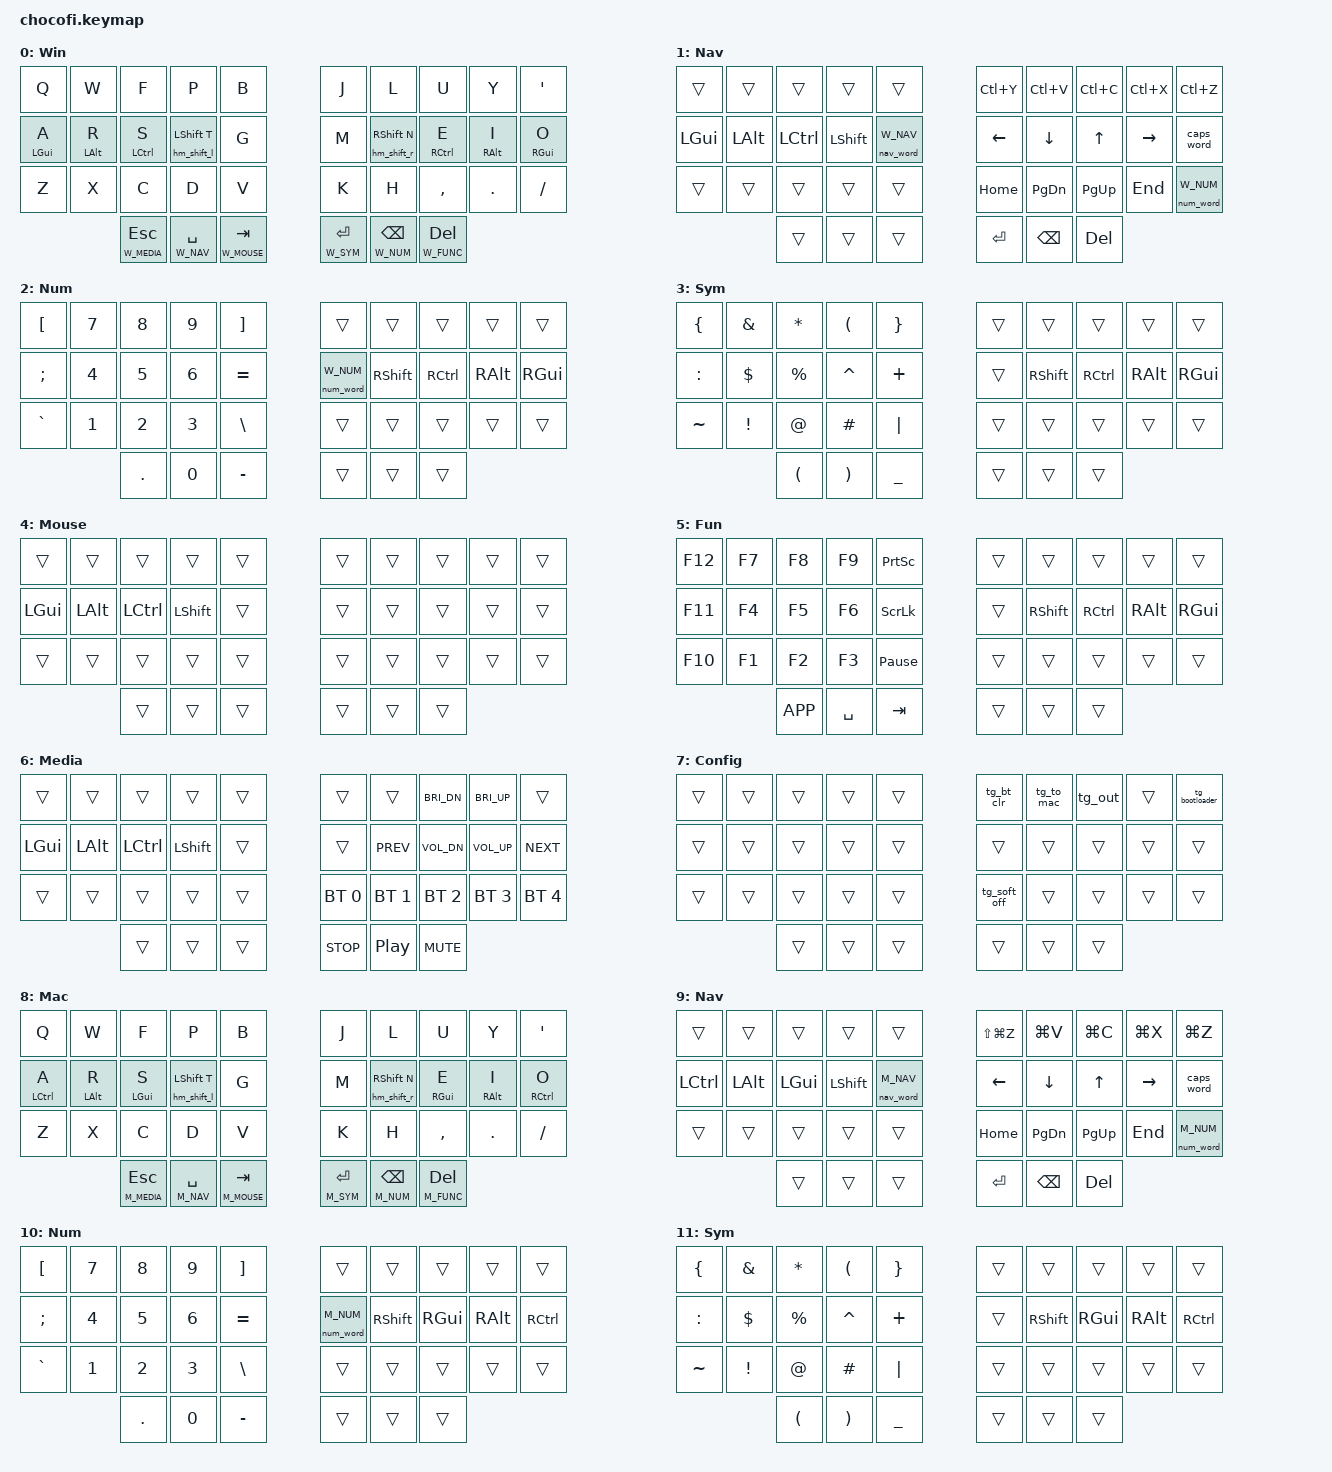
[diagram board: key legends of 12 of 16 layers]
#include <behaviors.dtsi>
#include <dt-bindings/zmk/keys.h>
#include <dt-bindings/zmk/bt.h>
#include <dt-bindings/zmk/outputs.h>

#include <zmk-helpers/helper.h>

#define ___ &trans

#define WIN       0
#define W_NAV     1
#define W_NUM     2
#define W_SYM     3
#define W_MOUSE   4
#define W_FUNC    5
#define W_MEDIA   6
#define W_CONFIG  7

#define MAC       8
#define M_NAV     9
#define M_NUM    10
#define M_SYM    11
#define M_MOUSE  12
#define M_FUNC   13
#define M_MEDIA  14
#define M_CONFIG 15

#include "settings.dtsi"
#include "behavior_homerow_mod.dtsi"
#include "behavior_tap_guard.dtsi"
#include "behavior_auto_layer.dtsi"

/ {
    conditional_layers {
        compatible = "zmk,conditional-layers";
        win_config_layer {
            if-layers = <W_MEDIA W_MOUSE>;
            then-layer = <W_CONFIG>;
        };
        mac_config_layer {
            if-layers = <M_MEDIA M_MOUSE>;
            then-layer = <M_CONFIG>;
        };
    };
};

&caps_word {
    continue-list = <UNDERSCORE MINUS BACKSPACE DELETE>;
};

/ {
    keymap {
        compatible = "zmk,keymap";

        win_layer {
            display-name = "Win";
            bindings = <
                // ╭────────────────────────┬────────────────────────┬────────────────────────┬────────────────────────┬────────────────────────╮    ╭────────────────────────┬────────────────────────┬────────────────────────┬───────────────────────┬────────────────────────╮
                      &kp Q                    &kp W                    &kp F                    &kp P                    &kp B                         &kp J                    &kp L                    &kp U                    &kp Y                   &kp SQT
                // ├────────────────────────┼────────────────────────┼────────────────────────┼────────────────────────┼────────────────────────┤    ├────────────────────────┼────────────────────────┼────────────────────────┼───────────────────────┼────────────────────────┤
                      &hm_l LGUI A             &hm_l LALT R             &hm_l LCTL S             &hm_shift_l LSHIFT T     &kp G                         &kp M                    &hm_shift_r RSHIFT N     &hm_r RCTL E             &hm_r RALT I            &hm_r RGUI O
                // ├────────────────────────┼────────────────────────┼────────────────────────┼────────────────────────┼────────────────────────┤    ├────────────────────────┼────────────────────────┼────────────────────────┼───────────────────────┼────────────────────────┤
                      &kp Z                    &kp X                    &kp C                    &kp D                    &kp V                         &kp K                    &kp H                    &kp COMMA                &kp DOT                 &kp FSLH
                // ╰────────────────────────┴────────────────────────┴────────────────────────┼────────────────────────┼────────────────────────┤    ├────────────────────────┼────────────────────────┼────────────────────────┼───────────────────────┼────────────────────────╯
                                                                        &lt W_MEDIA ESC          &lt W_NAV SPACE          &lt W_MOUSE TAB               &lt W_SYM RET            &lt W_NUM BSPC           &lt W_FUNC DEL
                //                                                   ╰────────────────────────┴────────────────────────┴────────────────────────╯    ╰────────────────────────┴────────────────────────┴────────────────────────╯
            >;
        };
        win_nav_layer {
            display-name = "Nav";
            bindings = <
                // ╭────────────────────────┬────────────────────────┬────────────────────────┬────────────────────────┬────────────────────────╮    ╭────────────────────────┬────────────────────────┬────────────────────────┬───────────────────────┬────────────────────────╮
                      ___                      ___                      ___                      ___                      ___                           &kp LC(Y)                &kp LC(V)                 &kp LC(C)                &kp LC(X)              &kp LC(Z)
                // ├────────────────────────┼────────────────────────┼────────────────────────┼────────────────────────┼────────────────────────┤    ├────────────────────────┼────────────────────────┼────────────────────────┼───────────────────────┼────────────────────────┤
                      &kp LGUI                 &kp LALT                 &kp LCTL                 &kp LSHIFT               &nav_word W_NAV               &kp LEFT                 &kp DOWN                  &kp UP                   &kp RIGHT              &caps_word
                // ├────────────────────────┼────────────────────────┼────────────────────────┼────────────────────────┼────────────────────────┤    ├────────────────────────┼────────────────────────┼────────────────────────┼───────────────────────┼────────────────────────┤
                      ___                      ___                      ___                      ___                      ___                           &kp HOME                 &kp PG_DN                 &kp PG_UP                &kp END                &num_word W_NUM
                // ╰────────────────────────┴────────────────────────┴────────────────────────┼────────────────────────┼────────────────────────┤    ├────────────────────────┼────────────────────────┼────────────────────────┼───────────────────────┼────────────────────────╯
                                                                        ___                      ___                      ___                           &kp RET                  &kp BSPC                  &kp DEL
                //                                                   ╰────────────────────────┴────────────────────────┴────────────────────────╯    ╰────────────────────────┴────────────────────────┴────────────────────────╯
            >;
        };
        win_num_layer {
            display-name = "Num";
            bindings = <
                // ╭────────────────────────┬────────────────────────┬────────────────────────┬────────────────────────┬────────────────────────╮    ╭────────────────────────┬────────────────────────┬────────────────────────┬───────────────────────┬────────────────────────╮
                      &kp LBKT                 &kp N7                   &kp N8                   &kp N9                   &kp RBKT                      ___                      ___                      ___                      ___                     ___
                // ├────────────────────────┼────────────────────────┼────────────────────────┼────────────────────────┼────────────────────────┤    ├────────────────────────┼────────────────────────┼────────────────────────┼───────────────────────┼────────────────────────┤
                      &kp SEMI                 &kp N4                   &kp N5                   &kp N6                   &kp EQUAL                     &num_word W_NUM          &kp RSHIFT               &kp RCTL                 &kp RALT                &kp RGUI
                // ├────────────────────────┼────────────────────────┼────────────────────────┼────────────────────────┼────────────────────────┤    ├────────────────────────┼────────────────────────┼────────────────────────┼───────────────────────┼────────────────────────┤
                      &kp GRAVE                &kp N1                   &kp N2                   &kp N3                   &kp BSLH                      ___                      ___                      ___                      ___                     ___
                // ╰────────────────────────┴────────────────────────┴────────────────────────┼────────────────────────┼────────────────────────┤    ├────────────────────────┼────────────────────────┼────────────────────────┼───────────────────────┼────────────────────────╯
                                                                        &kp DOT                  &kp N0                   &kp MINUS                     ___                      ___                      ___
                //                                                   ╰────────────────────────┴────────────────────────┴────────────────────────╯    ╰────────────────────────┴────────────────────────┴────────────────────────╯
            >;
        };
        win_sym_layer {
            display-name = "Sym";
            bindings = <
                // ╭────────────────────────┬────────────────────────┬────────────────────────┬────────────────────────┬────────────────────────╮    ╭────────────────────────┬────────────────────────┬────────────────────────┬───────────────────────┬────────────────────────╮
                      &kp LBRC                 &kp AMPS                 &kp STAR                 &kp LPAR                 &kp RBRC                      ___                      ___                      ___                      ___                     ___
                // ├────────────────────────┼────────────────────────┼────────────────────────┼────────────────────────┼────────────────────────┤    ├────────────────────────┼────────────────────────┼────────────────────────┼───────────────────────┼────────────────────────┤
                      &kp COLON                &kp DLLR                 &kp PRCNT                &kp CARET                &kp PLUS                      ___                      &kp RSHIFT               &kp RCTL                 &kp RALT                &kp RGUI
                // ├────────────────────────┼────────────────────────┼────────────────────────┼────────────────────────┼────────────────────────┤    ├────────────────────────┼────────────────────────┼────────────────────────┼───────────────────────┼────────────────────────┤
                      &kp TILDE                &kp EXCL                 &kp AT                   &kp HASH                 &kp PIPE                      ___                      ___                      ___                      ___                     ___
                // ╰────────────────────────┴────────────────────────┴────────────────────────┼────────────────────────┼────────────────────────┤    ├────────────────────────┼────────────────────────┼────────────────────────┼───────────────────────┼────────────────────────╯
                                                                        &kp LPAR                 &kp RPAR                 &kp UNDER                     ___                      ___                      ___
                //                                                   ╰────────────────────────┴────────────────────────┴────────────────────────╯    ╰────────────────────────┴────────────────────────┴────────────────────────╯
            >;
        };
        win_mouse_layer {
            display-name = "Mouse";
            bindings = <
                // ╭────────────────────────┬────────────────────────┬────────────────────────┬────────────────────────┬────────────────────────╮    ╭────────────────────────┬────────────────────────┬────────────────────────┬───────────────────────┬────────────────────────╮
                      ___                      ___                      ___                      ___                      ___                           ___                      ___                      ___                      ___                     ___
                // ├────────────────────────┼────────────────────────┼────────────────────────┼────────────────────────┼────────────────────────┤    ├────────────────────────┼────────────────────────┼────────────────────────┼───────────────────────┼────────────────────────┤
                      &kp LGUI                 &kp LALT                 &kp LCTL                 &kp LSHIFT               ___                           ___                      ___                      ___                      ___                     ___
                // ├────────────────────────┼────────────────────────┼────────────────────────┼────────────────────────┼────────────────────────┤    ├────────────────────────┼────────────────────────┼────────────────────────┼───────────────────────┼────────────────────────┤
                      ___                      ___                      ___                      ___                      ___                           ___                      ___                      ___                      ___                     ___
                // ╰────────────────────────┴────────────────────────┴────────────────────────┼────────────────────────┼────────────────────────┤    ├────────────────────────┼────────────────────────┼────────────────────────┼───────────────────────┼────────────────────────╯
                                                                        ___                      ___                      ___                           ___                      ___                      ___
                //                                                   ╰────────────────────────┴────────────────────────┴────────────────────────╯    ╰────────────────────────┴────────────────────────┴────────────────────────╯
            >;
        };
        win_func_layer {
            display-name = "Fun";
            bindings = <
                // ╭────────────────────────┬────────────────────────┬────────────────────────┬────────────────────────┬────────────────────────╮    ╭────────────────────────┬────────────────────────┬────────────────────────┬───────────────────────┬────────────────────────╮
                      &kp F12                  &kp F7                   &kp F8                   &kp F9                   &kp PSCRN                     ___                      ___                      ___                      ___                     ___
                // ├────────────────────────┼────────────────────────┼────────────────────────┼────────────────────────┼────────────────────────┤    ├────────────────────────┼────────────────────────┼────────────────────────┼───────────────────────┼────────────────────────┤
                      &kp F11                  &kp F4                   &kp F5                   &kp F6                   &kp SLCK                      ___                      &kp RSHIFT               &kp RCTL                 &kp RALT                &kp RGUI
                // ├────────────────────────┼────────────────────────┼────────────────────────┼────────────────────────┼────────────────────────┤    ├────────────────────────┼────────────────────────┼────────────────────────┼───────────────────────┼────────────────────────┤
                      &kp F10                  &kp F1                   &kp F2                   &kp F3                   &kp PAUSE_BREAK               ___                      ___                      ___                      ___                     ___
                // ╰────────────────────────┴────────────────────────┴────────────────────────┼────────────────────────┼────────────────────────┤    ├────────────────────────┼────────────────────────┼────────────────────────┼───────────────────────┼────────────────────────╯
                                                                        &kp K_APP                &kp SPACE                &kp TAB                       ___                      ___                      ___
                //                                                   ╰────────────────────────┴────────────────────────┴────────────────────────╯    ╰────────────────────────┴────────────────────────┴────────────────────────╯
            >;
        };
        win_media_layer {
            display-name = "Media";
            bindings = <
                // ╭────────────────────────┬────────────────────────┬────────────────────────┬────────────────────────┬────────────────────────╮    ╭────────────────────────┬────────────────────────┬────────────────────────┬───────────────────────┬────────────────────────╮
                      ___                      ___                      ___                      ___                      ___                           ___                      ___                      &kp C_BRI_DN             &kp C_BRI_UP            ___
                // ├────────────────────────┼────────────────────────┼────────────────────────┼────────────────────────┼────────────────────────┤    ├────────────────────────┼────────────────────────┼────────────────────────┼───────────────────────┼────────────────────────┤
                      &kp LGUI                 &kp LALT                 &kp LCTL                 &kp LSHIFT               ___                           ___                      &kp C_PREV               &kp K_VOL_DN             &kp K_VOL_UP            &kp C_NEXT
                // ├────────────────────────┼────────────────────────┼────────────────────────┼────────────────────────┼────────────────────────┤    ├────────────────────────┼────────────────────────┼────────────────────────┼───────────────────────┼────────────────────────┤
                      ___                      ___                      ___                      ___                      ___                           &bt BT_SEL 0             &bt BT_SEL 1             &bt BT_SEL 2             &bt BT_SEL 3            &bt BT_SEL 4
                // ╰────────────────────────┴────────────────────────┴────────────────────────┼────────────────────────┼────────────────────────┤    ├────────────────────────┼────────────────────────┼────────────────────────┼───────────────────────┼────────────────────────╯
                                                                        ___                      ___                      ___                           &kp C_STOP               &kp C_PP                 &kp C_MUTE
                //                                                   ╰────────────────────────┴────────────────────────┴────────────────────────╯    ╰────────────────────────┴────────────────────────┴────────────────────────╯
            >;
        };
        win_config_layer {
            display-name = "Config";
            bindings = <
                // ╭────────────────────────┬────────────────────────┬────────────────────────┬────────────────────────┬────────────────────────╮    ╭────────────────────────┬────────────────────────┬────────────────────────┬───────────────────────┬────────────────────────╮
                      ___                      ___                      ___                      ___                      ___                           &tg_bt_clr               &tg_to_mac               &tg_out                  ___                     &tg_bootloader
                // ├────────────────────────┼────────────────────────┼────────────────────────┼────────────────────────┼────────────────────────┤    ├────────────────────────┼────────────────────────┼────────────────────────┼───────────────────────┼────────────────────────┤
                      ___                      ___                      ___                      ___                      ___                           ___                      ___                      ___                      ___                     ___
                // ├────────────────────────┼────────────────────────┼────────────────────────┼────────────────────────┼────────────────────────┤    ├────────────────────────┼────────────────────────┼────────────────────────┼───────────────────────┼────────────────────────┤
                      ___                      ___                      ___                      ___                      ___                           &tg_soft_off             ___                      ___                      ___                     ___
                // ╰────────────────────────┴────────────────────────┴────────────────────────┼────────────────────────┼────────────────────────┤    ├────────────────────────┼────────────────────────┼────────────────────────┼───────────────────────┼────────────────────────╯
                                                                        ___                      ___                      ___                           ___                      ___                      ___
                //                                                   ╰────────────────────────┴────────────────────────┴────────────────────────╯    ╰────────────────────────┴────────────────────────┴────────────────────────╯
            >;
        };

	// ---
	// --- MacOS Layers
	// ---

        mac_layer {
            display-name = "Mac";
            bindings = <
                // ╭────────────────────────┬────────────────────────┬────────────────────────┬────────────────────────┬────────────────────────╮    ╭────────────────────────┬────────────────────────┬────────────────────────┬───────────────────────┬────────────────────────╮
                      &kp Q                    &kp W                    &kp F                    &kp P                    &kp B                         &kp J                    &kp L                    &kp U                    &kp Y                   &kp SQT
                // ├────────────────────────┼────────────────────────┼────────────────────────┼────────────────────────┼────────────────────────┤    ├────────────────────────┼────────────────────────┼────────────────────────┼───────────────────────┼────────────────────────┤
                      &hm_l LCTL A             &hm_l LALT R             &hm_l LGUI S             &hm_shift_l LSHIFT T     &kp G                         &kp M                    &hm_shift_r RSHIFT N     &hm_r RGUI E             &hm_r RALT I            &hm_r RCTL O
                // ├────────────────────────┼────────────────────────┼────────────────────────┼────────────────────────┼────────────────────────┤    ├────────────────────────┼────────────────────────┼────────────────────────┼───────────────────────┼────────────────────────┤
                      &kp Z                    &kp X                    &kp C                    &kp D                    &kp V                         &kp K                    &kp H                    &kp COMMA                &kp DOT                 &kp FSLH
                // ╰────────────────────────┴────────────────────────┴────────────────────────┼────────────────────────┼────────────────────────┤    ├────────────────────────┼────────────────────────┼────────────────────────┼───────────────────────┼────────────────────────╯
                                                                        &lt M_MEDIA ESC          &lt M_NAV SPACE          &lt M_MOUSE TAB               &lt M_SYM RET            &lt M_NUM BSPC           &lt M_FUNC DEL
                //                                                   ╰────────────────────────┴────────────────────────┴────────────────────────╯    ╰────────────────────────┴────────────────────────┴────────────────────────╯
            >;
        };
        mac_nav_layer {
            display-name = "Nav";
            bindings = <
                // ╭────────────────────────┬────────────────────────┬────────────────────────┬────────────────────────┬────────────────────────╮    ╭────────────────────────┬────────────────────────┬────────────────────────┬───────────────────────┬────────────────────────╮
                      ___                      ___                      ___                      ___                     ___                            &kp LS(LG(Z))            &kp LG(V)                &kp LG(C)                &kp LG(X)              &kp LG(Z)
                // ├────────────────────────┼────────────────────────┼────────────────────────┼────────────────────────┼────────────────────────┤    ├────────────────────────┼────────────────────────┼────────────────────────┼───────────────────────┼────────────────────────┤
                      &kp LCTL                 &kp LALT                 &kp LGUI                 &kp LSHIFT               &nav_word M_NAV               &kp LEFT                 &kp DOWN                 &kp UP                   &kp RIGHT              &caps_word
                // ├────────────────────────┼────────────────────────┼────────────────────────┼────────────────────────┼────────────────────────┤    ├────────────────────────┼────────────────────────┼────────────────────────┼───────────────────────┼────────────────────────┤
                      ___                      ___                      ___                      ___                      ___                           &kp HOME                 &kp PG_DN                &kp PG_UP                &kp END                &num_word M_NUM
                // ╰────────────────────────┴────────────────────────┴────────────────────────┼────────────────────────┼────────────────────────┤    ├────────────────────────┼────────────────────────┼────────────────────────┼───────────────────────┼────────────────────────╯
                                                                        ___                      ___                      ___                           &kp RET                  &kp BSPC                 &kp DEL
                //                                                   ╰────────────────────────┴────────────────────────┴────────────────────────╯    ╰────────────────────────┴────────────────────────┴────────────────────────╯
            >;
        };
        mac_num_layer {
            display-name = "Num";
            bindings = <
                // ╭────────────────────────┬────────────────────────┬────────────────────────┬────────────────────────┬────────────────────────╮    ╭────────────────────────┬────────────────────────┬────────────────────────┬───────────────────────┬────────────────────────╮
                      &kp LBKT                 &kp N7                   &kp N8                   &kp N9                   &kp RBKT                      ___                      ___                      ___                      ___                     ___
                // ├────────────────────────┼────────────────────────┼────────────────────────┼────────────────────────┼────────────────────────┤    ├────────────────────────┼────────────────────────┼────────────────────────┼───────────────────────┼────────────────────────┤
                      &kp SEMI                 &kp N4                   &kp N5                   &kp N6                   &kp EQUAL                     &num_word M_NUM          &kp RSHIFT               &kp RGUI                 &kp RALT                &kp RCTL
                // ├────────────────────────┼────────────────────────┼────────────────────────┼────────────────────────┼────────────────────────┤    ├────────────────────────┼────────────────────────┼────────────────────────┼───────────────────────┼────────────────────────┤
                      &kp GRAVE                &kp N1                   &kp N2                   &kp N3                   &kp BSLH                      ___                      ___                      ___                      ___                     ___
                // ╰────────────────────────┴────────────────────────┴────────────────────────┼────────────────────────┼────────────────────────┤    ├────────────────────────┼────────────────────────┼────────────────────────┼───────────────────────┼────────────────────────╯
                                                                        &kp DOT                  &kp N0                   &kp MINUS                     ___                      ___                      ___
                //                                                   ╰────────────────────────┴────────────────────────┴────────────────────────╯    ╰────────────────────────┴────────────────────────┴────────────────────────╯
            >;
        };
        mac_sym_layer {
            display-name = "Sym";
            bindings = <
                // ╭────────────────────────┬────────────────────────┬────────────────────────┬────────────────────────┬────────────────────────╮    ╭────────────────────────┬────────────────────────┬────────────────────────┬───────────────────────┬────────────────────────╮
                      &kp LBRC                 &kp AMPS                 &kp STAR                 &kp LPAR                 &kp RBRC                      ___                      ___                      ___                      ___                     ___
                // ├────────────────────────┼────────────────────────┼────────────────────────┼────────────────────────┼────────────────────────┤    ├────────────────────────┼────────────────────────┼────────────────────────┼───────────────────────┼────────────────────────┤
                      &kp COLON                &kp DLLR                 &kp PRCNT                &kp CARET                &kp PLUS                      ___                      &kp RSHIFT               &kp RGUI                 &kp RALT                &kp RCTL
                // ├────────────────────────┼────────────────────────┼────────────────────────┼────────────────────────┼────────────────────────┤    ├────────────────────────┼────────────────────────┼────────────────────────┼───────────────────────┼────────────────────────┤
                      &kp TILDE                &kp EXCL                 &kp AT                   &kp HASH                 &kp PIPE                      ___                      ___                      ___                      ___                     ___
                // ╰────────────────────────┴────────────────────────┴────────────────────────┼────────────────────────┼────────────────────────┤    ├────────────────────────┼────────────────────────┼────────────────────────┼───────────────────────┼────────────────────────╯
                                                                        &kp LPAR                 &kp RPAR                 &kp UNDER                     ___                      ___                      ___
                //                                                   ╰────────────────────────┴────────────────────────┴────────────────────────╯    ╰────────────────────────┴────────────────────────┴────────────────────────╯
            >;
        };
        mac_func_layer {
            display-name = "Fun";
            bindings = <
                // ╭────────────────────────┬────────────────────────┬────────────────────────┬────────────────────────┬────────────────────────╮    ╭────────────────────────┬────────────────────────┬────────────────────────┬───────────────────────┬────────────────────────╮
                      &kp F12                  &kp F7                   &kp F8                   &kp F9                   &kp PSCRN                     ___                      ___                      ___                      ___                     ___
                // ├────────────────────────┼────────────────────────┼────────────────────────┼────────────────────────┼────────────────────────┤    ├────────────────────────┼────────────────────────┼────────────────────────┼───────────────────────┼────────────────────────┤
                      &kp F11                  &kp F4                   &kp F5                   &kp F6                   &kp SLCK                      ___                      &kp RSHIFT               &kp RGUI                 &kp RALT                &kp RCTL
                // ├────────────────────────┼────────────────────────┼────────────────────────┼────────────────────────┼────────────────────────┤    ├────────────────────────┼────────────────────────┼────────────────────────┼───────────────────────┼────────────────────────┤
                      &kp F10                  &kp F1                   &kp F2                   &kp F3                   &kp PAUSE_BREAK               ___                      ___                      ___                      ___                     ___
                // ╰────────────────────────┴────────────────────────┴────────────────────────┼────────────────────────┼────────────────────────┤    ├────────────────────────┼────────────────────────┼────────────────────────┼───────────────────────┼────────────────────────╯
                                                                        &kp K_APP                &kp SPACE                &kp TAB                       ___                      ___                      ___
                //                                                   ╰────────────────────────┴────────────────────────┴────────────────────────╯    ╰────────────────────────┴────────────────────────┴────────────────────────╯
            >;
        };
        mac_media_layer {
            display-name = "Media";
            bindings = <
                // ╭────────────────────────┬────────────────────────┬────────────────────────┬────────────────────────┬────────────────────────╮    ╭────────────────────────┬────────────────────────┬────────────────────────┬───────────────────────┬────────────────────────╮
                      ___                      ___                      ___                      ___                     ___                            ___                      ___                      &kp C_BRI_DN             &kp C_BRI_UP            ___
                // ├────────────────────────┼────────────────────────┼────────────────────────┼────────────────────────┼────────────────────────┤    ├────────────────────────┼────────────────────────┼────────────────────────┼───────────────────────┼────────────────────────┤
                      &kp LCTL                 &kp LALT                 &kp LGUI                 &kp LSHIFT               ___                           ___                      &kp C_PREV               &kp K_VOL_DN             &kp K_VOL_UP            &kp C_NEXT
                // ├────────────────────────┼────────────────────────┼────────────────────────┼────────────────────────┼────────────────────────┤    ├────────────────────────┼────────────────────────┼────────────────────────┼───────────────────────┼────────────────────────┤
                      ___                      ___                      ___                      ___                      ___                           &bt BT_SEL 0             &bt BT_SEL 1             &bt BT_SEL 2            &bt BT_SEL 3             &bt BT_SEL 4
                // ╰────────────────────────┴────────────────────────┴────────────────────────┼────────────────────────┼────────────────────────┤    ├────────────────────────┼────────────────────────┼────────────────────────┼───────────────────────┼────────────────────────╯
                                                                        ___                      ___                      ___                           &kp C_STOP               &kp C_PP                 &kp C_MUTE
                //                                                   ╰────────────────────────┴────────────────────────┴────────────────────────╯    ╰────────────────────────┴────────────────────────┴────────────────────────╯
            >;
        };
        mac_mouse_layer {
            display-name = "Mouse";
            bindings = <
                // ╭────────────────────────┬────────────────────────┬────────────────────────┬────────────────────────┬────────────────────────╮    ╭────────────────────────┬────────────────────────┬────────────────────────┬───────────────────────┬────────────────────────╮
                      ___                      ___                      ___                      ___                     ___                            ___                      ___                      ___                      ___                     ___
                // ├────────────────────────┼────────────────────────┼────────────────────────┼────────────────────────┼────────────────────────┤    ├────────────────────────┼────────────────────────┼────────────────────────┼───────────────────────┼────────────────────────┤
                      &kp LCTL                 &kp LALT                 &kp LGUI                 &kp LSHIFT               ___                           ___                      ___                      ___                      ___                     ___
                // ├────────────────────────┼────────────────────────┼────────────────────────┼────────────────────────┼────────────────────────┤    ├────────────────────────┼────────────────────────┼────────────────────────┼───────────────────────┼────────────────────────┤
                      ___                      ___                      ___                      ___                      ___                           ___                      ___                      ___                      ___                     ___
                // ╰────────────────────────┴────────────────────────┴────────────────────────┼────────────────────────┼────────────────────────┤    ├────────────────────────┼────────────────────────┼────────────────────────┼───────────────────────┼────────────────────────╯
                                                                        ___                      ___                      ___                           ___                      ___                      ___
                //                                                   ╰────────────────────────┴────────────────────────┴────────────────────────╯    ╰────────────────────────┴────────────────────────┴────────────────────────╯
            >;
        };
        mac_config_layer {
            display-name = "Config";
            bindings = <
                // ╭────────────────────────┬────────────────────────┬────────────────────────┬────────────────────────┬────────────────────────╮    ╭────────────────────────┬────────────────────────┬────────────────────────┬───────────────────────┬────────────────────────╮
                      ___                      ___                      ___                      ___                     ___                            &tg_bt_clr               &tg_to_win               &tg_out                  ___                     &tg_bootloader
                // ├────────────────────────┼────────────────────────┼────────────────────────┼────────────────────────┼────────────────────────┤    ├────────────────────────┼────────────────────────┼────────────────────────┼───────────────────────┼────────────────────────┤
                      ___                      ___                      ___                      ___                     ___                            ___                      ___                      ___                      ___                     ___
                // ├────────────────────────┼────────────────────────┼────────────────────────┼────────────────────────┼────────────────────────┤    ├────────────────────────┼────────────────────────┼────────────────────────┼───────────────────────┼────────────────────────┤
                      ___                      ___                      ___                      ___                     ___                            &tg_soft_off             ___                      ___                      ___                     ___
                // ╰────────────────────────┴────────────────────────┴────────────────────────┼────────────────────────┼────────────────────────┤    ├────────────────────────┼────────────────────────┼────────────────────────┼───────────────────────┼────────────────────────╯
                                                                        ___                      ___                      ___                           ___                      ___                      ___
                //                                                   ╰────────────────────────┴────────────────────────┴────────────────────────╯    ╰────────────────────────┴────────────────────────┴────────────────────────╯
            >;
        };
    };
};
